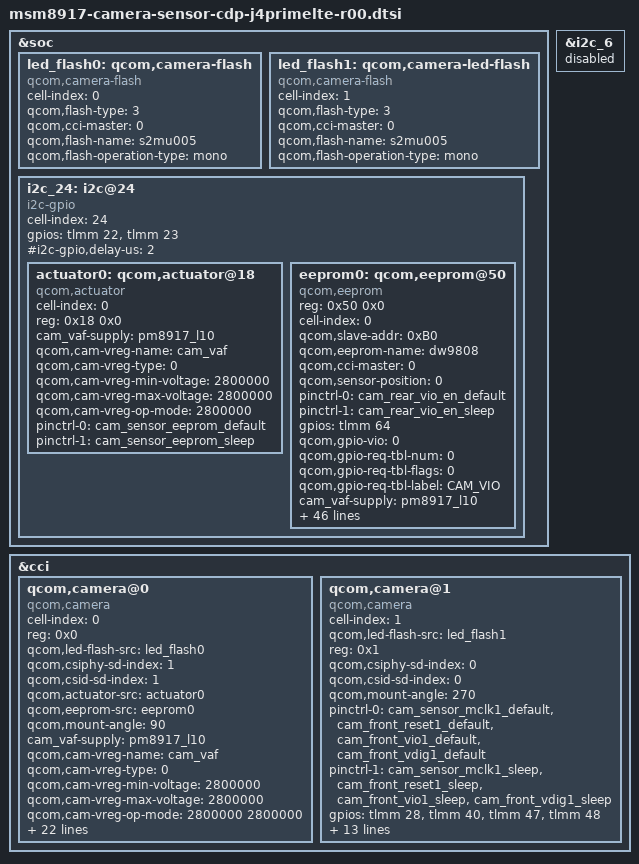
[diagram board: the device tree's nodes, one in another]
/*
 * Copyright (c) 2014, The Linux Foundation. All rights reserved.
 *
 * This program is free software; you can redistribute it and/or modify
 * it under the terms of the GNU General Public License version 2 and
 * only version 2 as published by the Free Software Foundation.
 *
 * This program is distributed in the hope that it will be useful,
 * but WITHOUT ANY WARRANTY; without even the implied warranty of
 * MERCHANTABILITY or FITNESS FOR A PARTICULAR PURPOSE.  See the
 * GNU General Public License for more details.
 */

&soc {
 	led_flash0: qcom,camera-flash {
                cell-index = <0>;
                compatible = "qcom,camera-flash";
                qcom,flash-type = <3>;
                qcom,cci-master = <0>;
                qcom,flash-name = "s2mu005";
                qcom,flash-operation-type = "mono";
        };
 	led_flash1: qcom,camera-led-flash {
		cell-index = <1>;
		compatible = "qcom,camera-flash";
		qcom,flash-type = <3>;
		qcom,cci-master = <0>;
		qcom,flash-name = "s2mu005";
                qcom,flash-operation-type = "mono";
	};
	i2c_24: i2c@24 {
                cell-index = <24>;
                compatible = "i2c-gpio";
                gpios = <&tlmm 22 0 /* sda */
                         &tlmm 23 0 /* scl */
                >;
                #i2c-gpio,delay-us = <2>;
                #address-cells = <1>;
                #size-cells = <0>;

                actuator0: qcom,actuator@18 {
                        compatible = "qcom,actuator";
                        cell-index = <0>;
                        reg = <0x18 0x0>;
                        cam_vaf-supply = <&pm8917_l10>;
                        qcom,cam-vreg-name =  "cam_vaf";
                        qcom,cam-vreg-type = <0>;
                        qcom,cam-vreg-min-voltage = <2800000>;
                        qcom,cam-vreg-max-voltage = <2800000>;
                        qcom,cam-vreg-op-mode = <2800000>;
                        pinctrl-names = "cam_sensor_eeprom_default", "cam_sensor_eeprom_sleep";
                        pinctrl-0 = <&cam_sensor_eeprom_default>;
                        pinctrl-1 = <&cam_sensor_eeprom_sleep>;

                };

                eeprom0: qcom,eeprom@50 {
					compatible = "qcom,eeprom";
					reg = <0x50 0x0>;
					cell-index = <0>;
					qcom,slave-addr = <0xB0>;
					qcom,eeprom-name = "dw9808";
					qcom,cci-master = <0>;
					qcom,sensor-position = <0>;
					pinctrl-names = "cam_sensor_eeprom_default", "cam_sensor_eeprom_sleep";
					pinctrl-0 = <&cam_rear_vio_en_default>;
					pinctrl-1 = <&cam_rear_vio_en_sleep>;
					gpios = <&tlmm 64 0>;
					qcom,gpio-vio = <0>;
					qcom,gpio-req-tbl-num = <0>;
					qcom,gpio-req-tbl-flags = <0>;
					qcom,gpio-req-tbl-label = "CAM_VIO";
					cam_vaf-supply = <&pm8917_l10>;
					qcom,cam-vreg-name = "cam_vaf";
					qcom,cam-vreg-type = <0>;
					qcom,cam-vreg-min-voltage = <2800000>;
					qcom,cam-vreg-max-voltage = <2800000>;
					qcom,cam-vreg-op-mode = <100000>;
					qcom,cam-power-seq-type = "sensor_vreg", "sensor_gpio";
					qcom,cam-power-seq-val = "cam_vaf", "sensor_gpio_vio";
					qcom,cam-power-seq-cfg-val = <1 1>;
					qcom,cam-power-seq-delay = <2 10>;
					qcom,num-blocks = <11>;
					qcom,page0 = <0 0 0 0 0 0>;
					qcom,poll0 = <0 0 0 0 0 0>;
					qcom,mem0 = <0xFC 0x00 2 0 1 0>;
					qcom,page1 = <0 0 0 0 0 0>;
					qcom,poll1 = <0 0 0 0 0 0>;
					qcom,mem1 = <0x4 0xFC 2 0 1 0>;
					qcom,page2 = <0 0 0 0 0 0>;
					qcom,poll2 = <0 0 0 0 0 0>;
					qcom,mem2 = <0x708 0x100 2 0 1 0>;
					qcom,page3 = <0 0 0 0 0 0>;
					qcom,poll3 = <0 0 0 0 0 0>;
					qcom,mem3 = <0x4 0x808 2 0 1 0>;
					qcom,page4 = <0 0 0 0 0 0>;
					qcom,poll4 = <0 0 0 0 0 0>;
					qcom,mem4 = <0x7A 0x80C 2 0 1 0>;
					qcom,page5 = <0 0 0 0 0 0>;
					qcom,poll5 = <0 0 0 0 0 0>;
					qcom,mem5 = <0x4 0x886 2 0 1 0>;
					qcom,page6 = <0 0 0 0 0 0>;
					qcom,poll6 = <0 0 0 0 0 0>;
					qcom,mem6 = <0x26 0x88A 2 0 1 0>;
					qcom,page7 = <0 0 0 0 0 0>;
					qcom,poll7 = <0 0 0 0 0 0>;
					qcom,mem7 = <0x4 0x8B0 2 0 1 0>;
					qcom,page8 = <0 0 0 0 0 0>;
					qcom,poll8 = <0 0 0 0 0 0>;
					qcom,mem8 = <0x38 0x8B4 2 0 1 0>;
					qcom,page9 = <0 0 0 0 0 0>;
					qcom,poll9 = <0 0 0 0 0 0>;
					qcom,mem9 = <0x4 0x8EC 2 0 1 0>;
					qcom,page10 = <0 0 0 0 0 0>;
					qcom,poll10 = <0 0 0 0 0 0>;
					qcom,mem10 = <0x10 0x8F0 2 0 1 0>;
					qcom,total-size = <0x900>;
		}; 
/*                eeprom1: qcom,eeprom@51 {
                        compatible = "qcom,eeprom";
                        reg = <0x51>;
                        cell-index = <1>;
                        qcom,slave-addr = <0xA2>;
                        qcom,eeprom-name = "m24128s";
                        cam_vio-supply = <&pm8916_l16>;
                        qcom,cam-vreg-name = "cam_vio";
                        qcom,cam-vreg-type = <0>;
                        qcom,cam-vreg-min-voltage = <1800000>;
                        qcom,cam-vreg-max-voltage = <1800000>;
                        qcom,cam-vreg-op-mode = <1800000>;
                        pinctrl-names = "eeprom_default", "eeprom_suspend";
                        pinctrl-0 = <&front_cam_sensor_eeprom_default>;
                        pinctrl-1 = <&front_cam_sensor_eeprom_sleep>;
                        qcom,sensor-position = <1>;
                        qcom,cam-power-seq-type = "sensor_vreg";
                        qcom,cam-power-seq-val = "cam_vio";
                        qcom,cam-power-seq-cfg-val = <1>;
                        qcom,cam-power-seq-delay =   <1>;
                        qcom,cal-num-blocks = <1>;
                        qcom,cal-page0 = <0 0 0 0 0 0>;
                        qcom,cal-poll0 = <0 0 0 0 0 0>;
                        qcom,cal-mem0 = <0x0B00 0x00 2 0 1 0>;
                };*/
        };
};

&i2c_6 {
 	status = "disable";
/* 	actuator0: qcom,actuator@18 {
	        compatible = "qcom,actuator";
		cell-index = <0>;
		qcom,cci-master = <0>;
		reg = <0x18 0x0>;
		cam_vaf-supply = <&pm8917_l10>;
		qcom,cam-vreg-name = "cam_vaf";
		qcom,cam-vreg-min-voltage = <2800000>;
		qcom,cam-vreg-max-voltage = <2800000>;
		qcom,cam-vreg-op-mode = <100000>;
	};*/
};

&cci {
	/* actuator0: qcom,actuator@18 {
		compatible = "qcom,actuator";
		cell-index = <0>;
		qcom,actuator-name = "zc535";
		qcom,cci-master = <0>;
		reg = <0x18 0x0>;
		cam_vaf-supply = <&pm8917_l10>;
		qcom,cam-vreg-name = "cam_vaf";
		qcom,cam-vreg-type = <0>;
		qcom,cam-vreg-min-voltage = <2800000>;
		qcom,cam-vreg-max-voltage = <2800000>;
		qcom,cam-vreg-op-mode = <100000>;
	};
	eeprom0: qcom,eeprom@50 {
		compatible = "qcom,eeprom";
		reg = <0xB0 0x0>;
		cell-index = <0>;
		qcom,slave-addr = <0xB0>;
		qcom,eeprom-name = "zc535";
		qcom,cci-master = <0>;
		qcom,sensor-position = <0>;
		pinctrl-names = "cam_default", "cam_suspend";
		pinctrl-0 = <&cam_vio_en_default>;
		pinctrl-1 = <&cam_vio_en_sleep>;
		gpios = <&tlmm 39 0>;
		qcom,gpio-vio = <0>;
		qcom,gpio-req-tbl-num = <0>;
		qcom,gpio-req-tbl-flags = <0>;
		qcom,gpio-req-tbl-label = "CAM_VIO";
		cam_vaf-supply = <&pm8917_l10>;
		qcom,cam-vreg-name = "cam_vaf";
		qcom,cam-vreg-type = <0>;
		qcom,cam-vreg-min-voltage = <2800000>;
		qcom,cam-vreg-max-voltage = <2800000>;
		qcom,cam-vreg-op-mode = <100000>;
		qcom,cam-power-seq-type = "sensor_vreg", "sensor_gpio";
		qcom,cam-power-seq-val = "cam_vaf", "sensor_gpio_vio";
		qcom,cam-power-seq-cfg-val = <1 1>;
		qcom,cam-power-seq-delay = <2 10>;

		qcom,num-blocks = <8>;
		qcom,page0 = <0 0 0 0 0 0>;
		qcom,poll0 = <0 0 0 0 0 0>;
		qcom,mem0 = <0xBF 0x00 2 0 1 0>;
		qcom,page1 = <0 0 0 0 0 0>;
		qcom,poll1 = <0 0 0 0 0 0>;
		qcom,mem1 = <0x4 0xFC 2 0 1 0>;
		qcom,page2 = <0 0 0 0 0 0>;
		qcom,poll2 = <0 0 0 0 0 0>;
		qcom,mem2 = <0x7B0 0x100 2 0 1 0>;
		qcom,page3 = <0 0 0 0 0 0>;
		qcom,poll3 = <0 0 0 0 0 0>;
		qcom,mem3 = <0x4 0x8FC 2 0 1 0>;
		qcom,page4 = <0 0 0 0 0 0>;
		qcom,poll4 = <0 0 0 0 0 0>;
		qcom,mem4 = <0x20 0x900 2 0 1 0>;
		qcom,page5 = <0 0 0 0 0 0>;
		qcom,poll5 = <0 0 0 0 0 0>;
		qcom,mem5 = <0x4 0x9FC 2 0 1 0>;
		qcom,page6 = <0 0 0 0 0 0>;
		qcom,poll6 = <0 0 0 0 0 0>;
		qcom,mem6 = <0x700 0xA00 2 0 1 0>;
		qcom,page7 = <0 0 0 0 0 0>;
		qcom,poll7 = <0 0 0 0 0 0>;
		qcom,mem7 = <0x4 0x11FC 2 0 1 0>;
		qcom,total-size = <0x1200>;
	}; 
	eeprom1: qcom,otp@53 {
		compatible = "qcom,otp";
		reg = <0x53 0x0>;
		cell-index = <1>;
		qcom,slave-addr = <0x20>;
		qcom,csiphy-sd-index = <1>;
		qcom,csid-sd-index = <1>;
		qcom,eeprom-name = "lsi_s5k5e3yx";
		cam_vana-supply = <&pm8917_l22>;
		qcom,cam-vreg-name = "cam_vana";
		qcom,cam-vreg-type = <0>;
		qcom,cam-vreg-min-voltage = <2800000>;
		qcom,cam-vreg-max-voltage = <2800000>;
		qcom,cam-vreg-op-mode = <2800000>;
		pinctrl-names = "cam_default", "cam_suspend";
		pinctrl-0 = <&cam_sensor_mclk1_default &cam_sensor_front_default &cam_vio_en_default &cam_core_en_default>;
		pinctrl-1 = <&cam_sensor_mclk1_sleep &cam_sensor_front_sleep &cam_vio_en_sleep &cam_core_en_sleep>;
		gpios = <&tlmm 27 0>,
			<&tlmm 38 0>,
			<&tlmm 39 0>,
			<&tlmm 92 0>;
		qcom,gpio-reset = <1>;
		qcom,gpio-vio = <2>;
		qcom,gpio-vdig = <3>;
		qcom,gpio-req-tbl-num = <0 1 2 3>;
		qcom,gpio-req-tbl-flags = <1 0 0 0>;
		qcom,gpio-req-tbl-label = "CAMIF_MCLK",
			"CAM_RESET1",
			"CAM_VIO",
			"CAM_VDIG";
		qcom,sensor-position = <1>;
		qcom,sensor-mode = <0>;
		qcom,cci-master = <1>;
		qcom,cam-power-seq-type = "sensor_vreg", "sensor_gpio", "sensor_gpio", "sensor_gpio", "sensor_gpio", "sensor_clk";
		qcom,cam-power-seq-val = "cam_vana", "sensor_gpio_vdig", "sensor_gpio_vio", "sensor_gpio_reset", "sensor_gpio_reset","sensor_cam_mclk";
		qcom,cam-power-seq-cfg-val = <1 1 1 0 1 24000000>;
		qcom,cam-power-seq-delay =   <1 1 1 0 2 1>;
		status = "ok";
		clocks = <&clock_gcc clk_mclk1_clk_src>,
			   <&clock_gcc clk_gcc_camss_mclk1_clk>;
		clock-names = "cam_src_clk", "cam_clk";
		qcom,clock-rates = <24000000 0>;
		qcom,num-blocks = <4>;
		qcom,page0 = <0 0 0 0 0 0>;
		qcom,poll0 = <0 0 0 0 0 0>;
		qcom,mem0 = <0x28 0x4 2 0 1 0>;
		qcom,page1 = <0 0 0 0 0 0>;
		qcom,poll1 = <0 0 0 0 0 0>;
		qcom,mem1 = <0x4 0x2C 2 0 1 0>;
		qcom,page2 = <0 0 0 0 0 0>;
		qcom,poll2 = <0 0 0 0 0 0>;
		qcom,mem2 = <0xA 0x30 2 0 1 0>;
		qcom,page3 = <0 0 0 0 0 0>;
		qcom,poll3 = <0 0 0 0 0 0>;
		qcom,mem3 = <0x4 0x3A 2 0 1 0>;
		qcom,total-size = <0x3E>;
	}; */
	qcom,camera@0 {
		cell-index = <0>;
		compatible = "qcom,camera";
		reg = <0x0>;
		qcom,led-flash-src = <&led_flash0>;
		qcom,csiphy-sd-index = <1>;
		qcom,csid-sd-index = <1>;
		qcom,actuator-src = <&actuator0>;	
		qcom,eeprom-src = <&eeprom0>;
		qcom,mount-angle = <90>;
		cam_vaf-supply = <&pm8917_l10>;
		qcom,cam-vreg-name ="cam_vaf";
		qcom,cam-vreg-type = <0>;
		qcom,cam-vreg-min-voltage = <2800000>;
		qcom,cam-vreg-max-voltage = <2800000>;
		qcom,cam-vreg-op-mode = <2800000 2800000>;
		pinctrl-names = "cam_default", "cam_suspend";
		pinctrl-0 = <&cam_sensor_mclk0_default &cam_sensor_rear_default &cam_rear_vio_en_default &cam_rear_vdig_en_default>;
		pinctrl-1 = <&cam_sensor_mclk0_sleep &cam_sensor_rear_sleep &cam_rear_vio_en_sleep &cam_rear_vdig_en_sleep>;
		gpios = <&tlmm 26 0>,
			<&tlmm 38 0>,
			<&tlmm 64 0>,
			<&tlmm 62 0>;
		qcom,gpio-reset = <1>;
		qcom,gpio-vio = <2>;
		qcom,gpio-vdig = <3>;
		qcom,gpio-req-tbl-num = <0 1 2 3>;
		qcom,gpio-req-tbl-flags = <1 0 0 0>;
		qcom,gpio-req-tbl-label = "CAMIF_MCLK",
			"CAM_RESET0",
			"CAM_VIO",
			"CAM_VDIG";
		qcom,sensor-position = <0>;
		qcom,sensor-mode = <0>;
		qcom,cci-master = <0>;
		status = "ok";
		clocks = <&clock_gcc clk_mclk0_clk_src>,
			   <&clock_gcc clk_gcc_camss_mclk0_clk>;
		clock-names = "cam_src_clk", "cam_clk";
		qcom,clock-rates = <24000000 0>;
	};
	qcom,camera@1 {
		cell-index = <1>;
		compatible = "qcom,camera";
		qcom,led-flash-src = <&led_flash1>;
		reg = <0x1>;
		qcom,csiphy-sd-index = <0>;
		qcom,csid-sd-index = <0>;
		/*qcom,eeprom-src = <&eeprom1>; */
		qcom,mount-angle = <270>;	
		pinctrl-names = "cam_default", "cam_suspend";
		pinctrl-0 = <&cam_sensor_mclk1_default &cam_front_reset1_default &cam_front_vio1_default &cam_front_vdig1_default>;
		pinctrl-1 = <&cam_sensor_mclk1_sleep &cam_front_reset1_sleep &cam_front_vio1_sleep &cam_front_vdig1_sleep>;
		gpios = <&tlmm 28 0>,
			<&tlmm 40 0>,
			<&tlmm 47 0>,
                        <&tlmm 48 0>;
		qcom,gpio-reset = <1>;
		qcom,gpio-vio = <2>;
                qcom,gpio-vdig = <3>;
		qcom,gpio-req-tbl-num = <0 1 2 3>;
		qcom,gpio-req-tbl-flags = <1 0 0 0>;
		qcom,gpio-req-tbl-label = "CAMIF_MCLK1",
			"CAM_RESET1",
			"CAM_VIO1",
                        "CAM_VDIG1";
		qcom,sensor-position = <1>;
		qcom,sensor-mode = <0>;
		qcom,cci-master = <1>;
		status = "ok";
                clocks = <&clock_gcc clk_mclk2_clk_src>,
		         <&clock_gcc clk_gcc_camss_mclk2_clk>;
		clock-names = "cam_src_clk", "cam_clk";
                qcom,clock-rates = <24000000 0>;
	};	
};

